VERSION ""

NS_ :

BS_:

BU_: DBG DRIVER GEO MOTOR SENSOR_BRIDGE

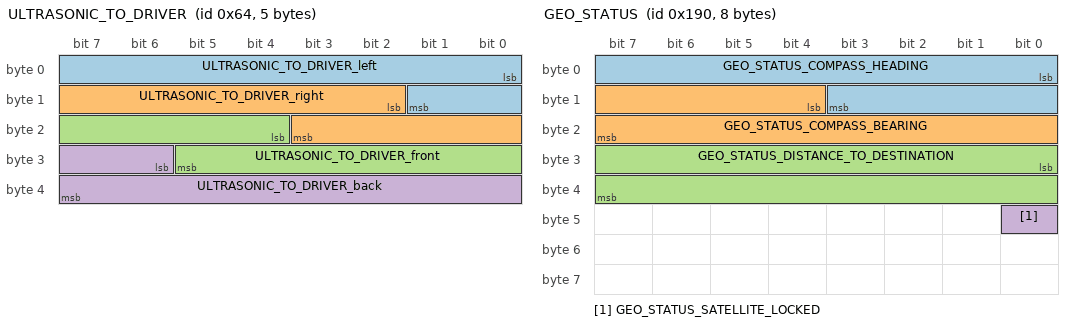
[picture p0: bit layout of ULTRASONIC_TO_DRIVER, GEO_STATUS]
BO_ 100 ULTRASONIC_TO_DRIVER: 5 SENSOR_BRIDGE
 SG_ ULTRASONIC_TO_DRIVER_left : 0|10@1+ (1,0) [0|511] "cm" DRIVER
 SG_ ULTRASONIC_TO_DRIVER_right : 10|10@1+ (1,0) [0|511] "cm" DRIVER
 SG_ ULTRASONIC_TO_DRIVER_front : 20|10@1+ (1,0) [0|511] "cm" DRIVER
 SG_ ULTRASONIC_TO_DRIVER_back : 30|10@1+ (1,0) [0|511] "cm" DRIVER

BO_ 300 GPS_DESTINATION: 8 SENSOR_BRIDGE
 SG_ GPS_DEST_LATITUDE_SCALED_100000 : 0|32@1- (1,0) [0|0] "Degrees" GEO
 SG_ GPS_DEST_LONGITUDE_SCALED_100000 : 32|32@1- (1,0) [0|0] "Degrees" GEO

BO_ 50 DRIVE_STATUS_CMD: 1 SENSOR_BRIDGE
 SG_ DRIVE_STATUS_CMD_start : 0|1@1+ (1,0) [0|0] "" MOTOR

BO_ 600 SELF_TEST_CMD: 1 SENSOR_BRIDGE
 SG_ SELF_TEST_CMD_start : 0|1@1+ (1,0) [0|0] "" MOTOR, GEO, DRIVER

BO_ 200 DRIVER_TO_MOTOR: 5 DRIVER
 SG_ DRIVER_TO_MOTOR_steer : 0|8@1- (1,0) [0|0] "degrees" MOTOR, SENSOR_BRIDGE
 SG_ DRIVER_TO_MOTOR_speed : 8|32@1- (1,0) [-50000|50000] "mph" MOTOR, SENSOR_BRIDGE

BO_ 610 DRIVER_SELF_TEST_RESULT: 1 DRIVER
 SG_ DRIVER_SELF_TEST_RESULT_status : 0|8@1+ (1,0) [0|0] "" SENSOR_BRIDGE

BO_ 400 GEO_STATUS: 8 GEO
  SG_ GEO_STATUS_COMPASS_HEADING : 0|12@1+ (1,0) [0|359] "Degrees" DRIVER, SENSOR_BRIDGE
  SG_ GEO_STATUS_COMPASS_BEARING : 12|12@1+ (1,0) [0|359] "Degrees" DRIVER, SENSOR_BRIDGE
  SG_ GEO_STATUS_DISTANCE_TO_DESTINATION : 24|16@1+ (0.1,0) [0|0] "Meters" DRIVER, SENSOR_BRIDGE
  SG_ GEO_STATUS_SATELLITE_LOCKED : 40|1@1+ (1,0) [0|0] "" DRIVER, SENSOR_BRIDGE

BO_ 620 GEO_SELF_TEST_RESULT: 1 GEO
 SG_ GEO_SELF_TEST_RESULT_status : 0|8@1+ (1,0) [0|0] "" SENSOR_BRIDGE

BO_ 650 GEO_CURRENT_COORDS: 8 SENSOR_BRIDGE
 SG_ CURR_LATITUDE_SCALED_100000 : 0|32@1- (1,0) [0|0] "Degrees" SENSOR_BRIDGE
 SG_ CURR_LONGITUDE_SCALED_100000 : 32|32@1- (1,0) [0|0] "Degrees" SENSOR_BRIDGE

BO_ 500 MOTOR_TO_APP_DBG: 5 MOTOR
 SG_ MOTOR_TO_APP_DBG_current_steer : 0|8@1- (1,0) [0|0] "degrees" SENSOR_BRIDGE
 SG_ MOTOR_TO_APP_DBG_current_speed : 8|32@1- (1,0) [-50000|50000] "mph" SENSOR_BRIDGE

BO_ 620 MOTOR_SELF_TEST_RESULT: 1 MOTOR
 SG_ MOTOR_SELF_TEST_RESULT_status : 0|8@1+ (1,0) [0|0] "" SENSOR_BRIDGE

CM_ BU_ DRIVER "The LED display and driver controller driving the car";
CM_ BU_ MOTOR "The RPM sensor, DC and servo motor controller of the car";
CM_ BU_ SENSOR_BRIDGE "The Bluetooth and the sonar sensor controller of the car";
CM_ BU_ GEO "The GPS and compass sensor controller of the car";

BA_DEF_ "BusType" STRING ;
BA_DEF_ BO_ "GenMsgCycleTime" INT 0 0;

BA_DEF_DEF_ "BusType" "CAN";
BA_DEF_DEF_ "GenMsgCycleTime" 0;

BA_ "GenMsgCycleTime" BO_ 100 1000;
BA_ "GenMsgCycleTime" BO_ 200 50;
